# T113-S3 register map
Vendor: Allwinner; Series: T113-S3; File version: 0.1
CPU: other 0, little endian, MPU, no FPU, 0 interrupt priority bits
Registers are 32-bit, read-write, reset 0x0 unless marked. A register's access mark holds for its fields unless they carry their own. Offsets are from the block's base; [hi:lo] are bit positions; lines under a group give offsets from that group; {n}, {i} and the like mark numbered series.

## DMAC
Base 0x03002000
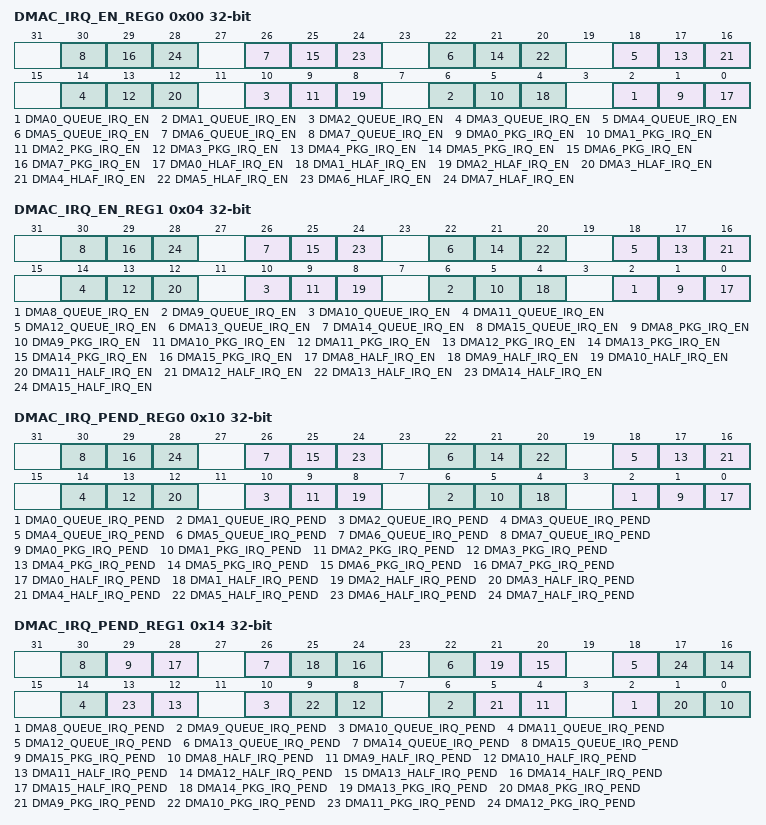
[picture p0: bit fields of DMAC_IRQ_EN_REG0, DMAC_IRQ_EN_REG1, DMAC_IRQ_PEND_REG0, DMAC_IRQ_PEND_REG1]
0x00 DMAC_IRQ_EN_REG0 — DMAC IRQ Enable Register 0
  [all] fields
    0=Disabled; 1=Enabled
  [4n+2] DMA{n}_QUEUE_IRQ_EN (n=0..7) — Enable the queue end interrupt of DMA channel {n} 0: Disabled 1: Enabled
  [4n+1] DMA{n}_PKG_IRQ_EN (n=0..7) — Enable the package end interrupt of DMA channel {n} 0: Disabled 1: Enabled
  [4n] DMA{n}_HLAF_IRQ_EN (n=0..7) — Enable the half package interrupt of DMA channel {n} 0: Disabled 1: Enabled
0x04 DMAC_IRQ_EN_REG1 — DMAC IRQ Enable Register 1
  [all] fields
    0=Disabled; 1=Enabled
  [4n-30] DMA{n}_QUEUE_IRQ_EN (n=8..15) — Enable the queue end interrupt of DMA channel {n} 0: Disabled 1: Enabled
  [4n-31] DMA{n}_PKG_IRQ_EN (n=8..15) — Enable the package end interrupt of DMA channel {n} 0: Disabled 1: Enabled
  [4n-32] DMA{n}_HALF_IRQ_EN (n=8..15) — Enable the half package interrupt of DMA channel {n} 0: Disabled 1: Enabled
0x10 DMAC_IRQ_PEND_REG0 — DMAC IRQ Pending Register 0
  [all] fields
    0=No_effect; 1=Pending
  [4n+2] DMA{n}_QUEUE_IRQ_PEND write-1-clears (n=0..7) — The IRQ pending bit for the queue end interrupt of the DMA channel {n}. Write 1 to clear the pending status. 0: No effect 1: Pending
  [4n+1] DMA{n}_PKG_IRQ_PEND write-1-clears (n=0..7) — The IRQ pending bit for the package end interrupt of the DMA channel {n}. Write 1 to clear the pending status. 0: No effect 1: Pending
  [4n] DMA{n}_HALF_IRQ_PEND write-1-clears (n=0..7) — The IRQ pending bit for the half package interrupt of the DMA channel {n}. Write 1 to clear the pending status. 0: No effect 1: Pending
0x14 DMAC_IRQ_PEND_REG1 — DMAC IRQ Pending Register 1
  [all] fields
    0=No_effect; 1=Pending
  [4n-30] DMA{n}_QUEUE_IRQ_PEND write-1-clears (n=8..15) — The IRQ pending bit for the queue end interrupt of the DMA channel {n}. Write 1 to clear the pending status. 0: No effect 1: Pending
  [29] DMA15_PKG_IRQ_PEND write-1-clears — The IRQ pending bit for the package end interrupt of the DMA channel 15. Write 1 to clear the pending status. 0: No effect 1: Pending
  [4n-32] DMA{n}_HALF_IRQ_PEND write-1-clears (n=8..15) — The IRQ pending bit for the half package interrupt of the DMA channel {n}. Write 1 to clear the pending status. 0: No effect 1: Pending
  [25] DMA14_PKG_IRQ_PEND write-1-clears — The IRQ pending bit for the package end interrupt of the DMA channel 14. Write 1 to clear the pending status. 0: No effect 1: Pending
  [21] DMA13_PKG_IRQ_PEND write-1-clears — The IRQ pending bit for the package end interrupt of the DMA channel 13. Write 1 to clear the pending status. 0: No effect 1: Pending.
  [4n-31] DMA{n}_PKG_IRQ_PEND write-1-clears (n=8..12) — The IRQ pending bit for the package end interrupt of the DMA channel {n}. Write 1 to clear the pending status. 0: No effect 1: Pending
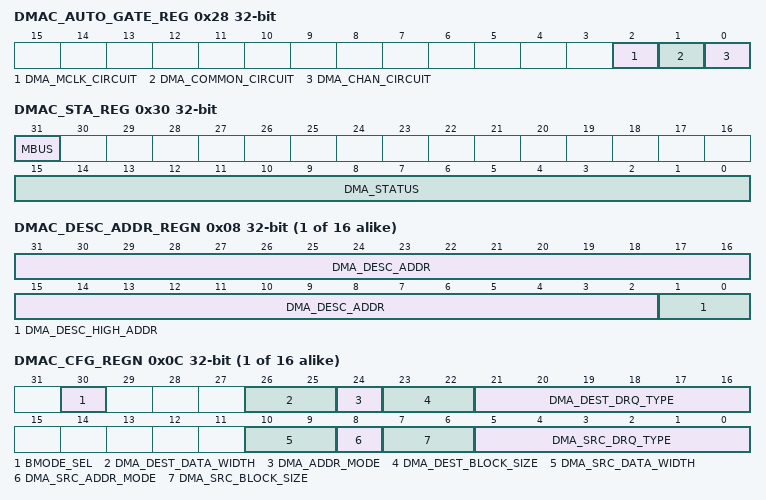
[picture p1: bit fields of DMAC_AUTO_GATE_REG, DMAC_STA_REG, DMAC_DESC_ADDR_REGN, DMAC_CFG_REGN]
0x28 DMAC_AUTO_GATE_REG — DMAC Auto Gating Register
  [all] fields
    0=Auto_gating_enabled; 1=Auto_gating_disabled
  [2] DMA_MCLK_CIRCUIT — Auto gating bit of DMA MCLK interface circuit 0: Auto gating enabled 1: Auto gating disabled
  [1] DMA_COMMON_CIRCUIT — Auto gating bit of DMA common circuit 0: Auto gating enabled 1: Auto gating disabled
  [0] DMA_CHAN_CIRCUIT — Auto gating bit of DMA channel circuit 0: Auto gating enabled 1: Auto gating disabled
0x30 DMAC_STA_REG — DMAC Status Register
  [31] MBUS ro — FIFO Status 0: Empty 1: Not Empty
    0=Empty; 1=Not_Empty
  [15:0] DMA_STATUS ro — DMA Channel[15:0] Status The meaning of each bit: 0: Idle 1: Busy
{0x100+0x40*i} _N[{i}] (i=0..15) group
  0x00 DMAC_EN_REGN — DMAC Channel Enable Register N (N = 0 to 15)
    [0] DMA_EN — DMA Channel Enable 0: Disabled 1: Enabled
      0=Disabled; 1=Enabled
  0x04 DMAC_PAU_REGN — DMAC Channel Pause Register N (N = 0 to 15)
    [0] DMA_PAUSE — Pause the DMA Channel Transfer Data 0: Resume Transferring 1: Pause Transferring
      0=Resume Transferring; 1=Pause Transferring
  0x08 DMAC_DESC_ADDR_REGN — DMAC Channel Start Address Register N (N = 0 to 15)
    [31:2] DMA_DESC_ADDR — Lower 30 bits of DMA channel descriptor address The descriptor address must be word-aligned.
    [1:0] DMA_DESC_HIGH_ADDR — Higher 2 bits of DMA channel descriptor high address The real address is as follows. DMA Channel Descriptor Address = {bit[1:0], bit[31:2], 2`b00}
  0x0C DMAC_CFG_REGN — DMAC Channel Configuration Register N (N = 0 to 15)
    [30] BMODE_SEL ro — 0: Normal Mode 1: BMODE
      0=Normal Mode; 1=BMODE
    [26:25] DMA_DEST_DATA_WIDTH ro — DMA Destination Data Width 00: 8-bit 01: 16-bit 10: 32-bit 11: 64-bit
      0=_8_bit; 1=_16_bit; 2=_32_bit; 3=_64_bit
    [24] DMA_ADDR_MODE ro — DMA Destination Address Mode 0: Linear Mode 1: IO Mode
      0=Linear Mode; 1=IO (IO Mode)
    [23:22] DMA_DEST_BLOCK_SIZE ro — DMA Destination Block Size 00: 1 01: 4 10: 8 11: 16
      0=_1; 1=_4; 2=_8; 3=_16
    [21:16] DMA_DEST_DRQ_TYPE ro — DMA Destination DRQ Type The details in DRQ Type and Port Corresponding Relation.
    [10:9] DMA_SRC_DATA_WIDTH ro — DMA Source Data Width 00: 8-bit 01: 16-bit 10: 32-bit 11: 64-bit
      0=_8_bit; 1=_16_bit; 2=_32_bit; 3=_64_bit
    [8] DMA_SRC_ADDR_MODE ro — DMA Source Address Mode 0: Linear Mode 1: IO Mode
      0=Linear Mode; 1=IO (IO Mode)
    [7:6] DMA_SRC_BLOCK_SIZE ro — DMA Source Block Size 00: 1 01: 4 10: 8 11: 16
      0=_1; 1=_4; 2=_8; 3=_16
    [5:0] DMA_SRC_DRQ_TYPE ro — DMA Source DRQ Type The details in DRQ Type and Port Corresponding Relation.
  0x10 DMAC_CUR_SRC_REGN — DMAC Channel Current Source Register N (N = 0 to 15)
    [31:0] DMA_CUR_SRC ro — DMA Channel Current Source Address.
  0x14 DMAC_CUR_DEST_REGN — DMAC Channel Current Destination Register N (N = 0 to 15)
    [31:0] DMA_CUR_DEST ro — DMA Channel Current Destination Address.
  0x18 DMAC_BCNT_LEFT_REGN — DMAC Channel Byte Counter Left Register N (N = 0 to 15)
    [24:0] DMA_BCNT_LEFT ro — DMA Channel Byte Counter Left.
  0x1C DMAC_PARA_REGN — DMAC Channel Parameter Register N (N = 0 to 15)
    [7:0] WAIT_CYC ro — Wait Clock Cycles
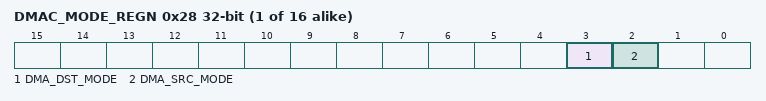
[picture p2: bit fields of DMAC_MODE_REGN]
  0x28 DMAC_MODE_REGN — DMAC Mode Register N (N = 0 to 15)
    [3] DMA_DST_MODE — Destination Communication Mode Select 0: Waiting mode 1: Handshake mode
      0=Waiting_mode; 1=Handshake_mode
    [2] DMA_SRC_MODE — Source Communication Mode Select 0: Waiting mode 1: Handshake mode
      0=Waiting_mode; 1=Handshake_mode
  0x2C DMAC_FDESC_ADDR_REGN — DMAC Former Descriptor Address Register N (N = 0 to 15)
    [31:0] DMA_FDESC_ADDR ro — This register is used to store the former value of DMA Channel Descriptor Address Register.
  0x30 DMAC_PKG_NUM_REGN — DMAC Package Number Register N (N = 0 to 15)
    [31:0] DMA_PKG_NUM ro — This register records the number of packages which has been completed in one transmission.
